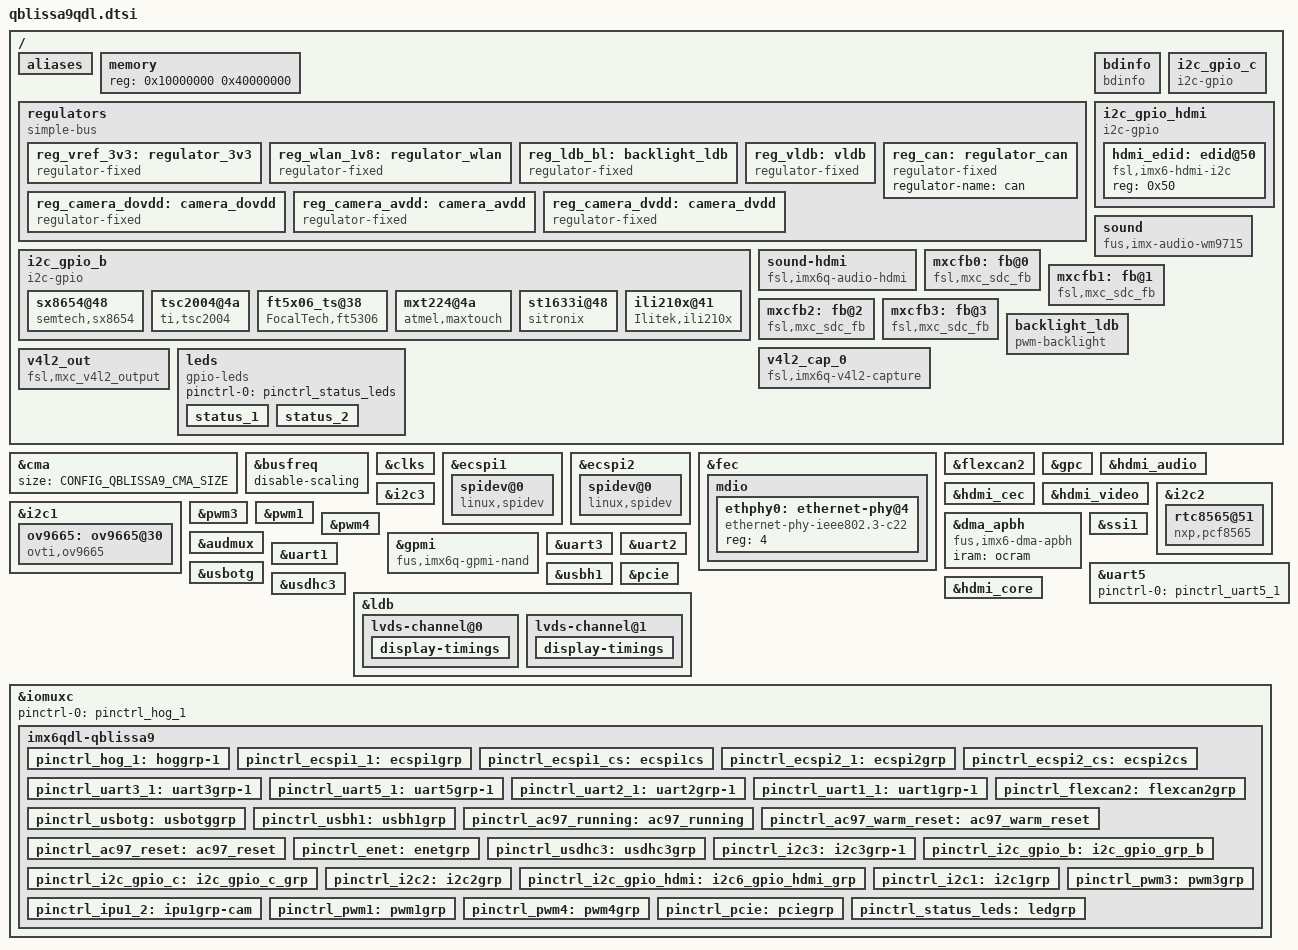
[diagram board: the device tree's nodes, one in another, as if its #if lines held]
/*
 * Copyright 2016-2017 F&S Elektronik Systeme GmbH
 *
 * This program is free software; you can redistribute it and/or modify
 * it under the terms of the GNU General Public License version 2 as
 * published by the Free Software Foundation.
 */

#include <dt-bindings/pwm/pwm.h>

/* Do we have HDMI? */
#if ((CONFIG_QBLISSA9_MXCFB0 == DISPLAY_HDMI) \
    || (CONFIG_QBLISSA9_MXCFB1 == DISPLAY_HDMI) \
    || (CONFIG_QBLISSA9_MXCFB2 == DISPLAY_HDMI) \
    || (CONFIG_QBLISSA9_MXCFB3 == DISPLAY_HDMI))
#define CONFIG_QBLISSA9_HDMI
#define CONFIG_QBLISSA9_HDMI_AUDIO
#define CONFIG_QBLISSA9_HDMI_CEC
#if ((CONFIG_QBLISSA9_MXCFB0 == DISPLAY_HDMI) \
    || (CONFIG_QBLISSA9_MXCFB1 == DISPLAY_HDMI))
#define __HDMI_ON_0_OR_1__	1
#define __HDMI_ON_2_OR_3__	0
#else
#define __HDMI_ON_0_OR_1__	0
#define __HDMI_ON_2_OR_3__	1
#endif
#endif

/* Do we have LVDS0? */
#if ((CONFIG_QBLISSA9_MXCFB0 == DISPLAY_LVDS0) \
    || (CONFIG_QBLISSA9_MXCFB1 == DISPLAY_LVDS0) \
    || (CONFIG_QBLISSA9_MXCFB2 == DISPLAY_LVDS0) \
    || (CONFIG_QBLISSA9_MXCFB3 == DISPLAY_LVDS0))
#define CONFIG_QBLISSA9_LVDS0
#if ((CONFIG_QBLISSA9_MXCFB0 == DISPLAY_LVDS0) \
    || (CONFIG_QBLISSA9_MXCFB1 == DISPLAY_LVDS0))
#define __LVDS0_ON_0_OR_1__	1
#define __LVDS0_ON_2_OR_3__	0
#else
#define __LVDS0_ON_0_OR_1__	0
#define __LVDS0_ON_2_OR_3__	1
#endif
#endif

/* Do we have LVDS1? */
#if ((CONFIG_QBLISSA9_MXCFB0 == DISPLAY_LVDS1) \
    || (CONFIG_QBLISSA9_MXCFB1 == DISPLAY_LVDS1) \
    || (CONFIG_QBLISSA9_MXCFB2 == DISPLAY_LVDS1) \
    || (CONFIG_QBLISSA9_MXCFB3 == DISPLAY_LVDS1))
#define CONFIG_QBLISSA9_LVDS1
#if ((CONFIG_QBLISSA9_MXCFB0 == DISPLAY_LVDS1) \
    || (CONFIG_QBLISSA9_MXCFB1 == DISPLAY_LVDS1))
#define __LVDS1_ON_0_OR_1__	1
#define __LVDS1_ON_2_OR_3__	0
#else
#define __LVDS1_ON_0_OR_1__	0
#define __LVDS1_ON_2_OR_3__	1
#endif
#endif

/* Check which LVDS will be the primary display */
#if (CONFIG_QBLISSA9_MXCFB0 == DISPLAY_LVDS0)
#define __LVDS0_PRIMARY__
#elif (CONFIG_QBLISSA9_MXCFB0 == DISPLAY_LVDS1)
#define __LVDS1_PRIMARY__
#elif (CONFIG_QBLISSA9_MXCFB1 == DISPLAY_LVDS0)
#define __LVDS0_PRIMARY__
#elif (CONFIG_QBLISSA9_MXCFB1 == DISPLAY_LVDS1)
#define __LVDS1_PRIMARY__
#elif (CONFIG_QBLISSA9__MXCFB2 == DISPLAY_LVDS0)
#define __LVDS0_PRIMARY__
#elif (CONFIG_QBLISSA9_MXCFB2 == DISPLAY_LVDS1)
#define __LVDS1_PRIMARY__
#elif (CONFIG_QBLISSA9_MXCFB3 == DISPLAY_LVDS0)
#define __LVDS0_PRIMARY__
#elif (CONFIG_QBLISSA9_MXCFB3 == DISPLAY_LVDS1)
#define __LVDS1_PRIMARY__
#endif

/* Check for invalid CONFIG combinations */

/* If SD_A is not active, also CD, WP and bus width may not be used */
#ifndef CONFIG_QBLISSA9_SD_A
#undef CONFIG_QBLISSA9_SD_A_CD
#undef CONFIG_QBLISSA9_SD_A_WP
#undef CONFIG_QBLISSA9_SD_A_8BIT
#endif

/ {
	aliases {
		mxcfb0 = &mxcfb0;
		mxcfb1 = &mxcfb1;
		mxcfb2 = &mxcfb2;
		mxcfb3 = &mxcfb3;
#ifdef CONFIG_QBLISSA9_I2C_B
		i2c3 = &i2c_gpio_b;
#endif
#ifdef CONFIG_QBLISSA9_I2C_C
		i2c4 = &i2c_gpio_c;
#endif
#ifdef CONFIG_QBLISSA9_HDMI
		i2c5 = &i2c_gpio_hdmi;
#endif
		};

	memory {
		reg = <0x10000000 0x40000000>;
	};

	regulators {
		compatible = "simple-bus";

		reg_vref_3v3: regulator_3v3 {
			compatible = "regulator-fixed";
			regulator-name = "vref-3V3";
			regulator-min-microvolt = <3300000>;
			regulator-max-microvolt = <3300000>;
			regulator-always-on;
		};

		/* USB_OTG_PWR handled by USB controller, no regulator needed */
#if 0 //###
		reg_usb_otg_vbus: usb_otg_vbus {
			compatible = "regulator-fixed";
			regulator-name = "usb_otg_vbus";
			regulator-min-microvolt = <5000000>;
			regulator-max-microvolt = <5000000>;
			/* Switchable starting with board rev. 1.30 */
#if CONFIG_QBLISSA9_BOARD_REVISION < 130
			regulator-always-on;
#else
			gpio = <&gpio3 22 GPIO_ACTIVE_HIGH>;
#endif
		};
#endif //###

		/* USB_H1_PWR is always on, no regulator needed */
#if 0 //###
		reg_usb_h1_vbus: usb_h1_vbus {
			compatible = "regulator-fixed";
			regulator-name = "usb_h1_vbus";
			regulator-min-microvolt = <5000000>;
			regulator-max-microvolt = <5000000>;
			/* No way to switch USB1_H1_VBUS power */
		};
#endif //###

#ifdef CONFIG_QBLISSA9_WLAN
		reg_wlan_1v8: regulator_wlan {
			compatible = "regulator-fixed";
			regulator-name = "vqmmc-wlan-1v8";
			regulator-min-microvolt = <1800000>;
			regulator-max-microvolt = <1800000>;
			regulator-always-on;
		};
#endif

		/* LVDS backlight */
		reg_ldb_bl: backlight_ldb {
			compatible = "regulator-fixed";
			regulator-name = "ldb-bl";
			gpio = <&gpio2 8 GPIO_ACTIVE_HIGH>;
			regulator-min-microvolt = <3300000>;
			regulator-max-microvolt = <3300000>;
			enable-active-high;
		};

		/* LVDS logic supply power */
		reg_vldb: vldb {
			compatible = "regulator-fixed";
			regulator-name = "VLDB";
			gpio = <&gpio2 11 GPIO_ACTIVE_HIGH>;
			regulator-min-microvolt = <3300000>;
			regulator-max-microvolt = <3300000>;
			enable-active-high;
		};

		/* CAN */
		reg_can: regulator_can {
			compatible = "regulator-fixed";
			regulator-name = "can";
		};

#ifdef CONFIG_QBLISSA9_PARALLEL_CAMERA
		reg_camera_dovdd: camera_dovdd {
			compatible = "regulator-fixed";
			regulator-name = "DOVDD-supply";
			regulator-min-microvolt = <1800000>;
			regulator-max-microvolt = <1800000>;
		};

		reg_camera_avdd: camera_avdd {
			compatible = "regulator-fixed";
			regulator-name = "VAVDD-supply";
			regulator-min-microvolt = <2800000>;
			regulator-max-microvolt = <2800000>;
		};

		reg_camera_dvdd: camera_dvdd {
			compatible = "regulator-fixed";
			regulator-name = "DVDD-supply";
			regulator-min-microvolt = <1500000>;
			regulator-max-microvolt = <1500000>;
		};
#endif /* CONFIG_QBLISSA9_PARALLEL_CAMERA */
	};

	/* F&S board information */
	bdinfo: bdinfo {
		compatible = "bdinfo";
		board_name = "qblissa9";
		ecc_strength = "8";
	};

#ifdef CONFIG_QBLISSA9_I2C_B
	i2c_gpio_b: i2c_gpio_b {
		compatible = "i2c-gpio";
		gpios = <&gpio4 21 GPIO_ACTIVE_HIGH /* sda */
			 &gpio4 22 GPIO_ACTIVE_HIGH /* scl */
			>;
		pinctrl-names = "default";
		pinctrl-0 = <&pinctrl_i2c_gpio_b>;
		i2c-gpio,delay-us = <2>;	/* ~100 kHz */
		#address-cells = <1>;
		#size-cells = <0>;
	};
#endif

#ifdef CONFIG_QBLISSA9_I2C_C
	i2c_gpio_c: i2c_gpio_c {
		compatible = "i2c-gpio";
		gpios = <&gpio2 12 GPIO_ACTIVE_HIGH /* sda */
			 &gpio2 13 GPIO_ACTIVE_HIGH /* scl */
			>;
		pinctrl-names = "default";
		pinctrl-0 = <&pinctrl_i2c_gpio_c>;
		i2c-gpio,delay-us = <2>;	/* ~100 kHz */
		#address-cells = <1>;
		#size-cells = <0>;
	};
#endif

#ifdef CONFIG_QBLISSA9_HDMI
	i2c_gpio_hdmi: i2c_gpio_hdmi {
		compatible = "i2c-gpio";
		gpios = <&gpio2 14 GPIO_ACTIVE_HIGH /* sda */
			 &gpio2 15 GPIO_ACTIVE_HIGH /* scl */
			>;
		pinctrl-names = "default";
		pinctrl-0 = <&pinctrl_i2c_gpio_hdmi>;
		//i2c-gpio,sda-open-drain;
		//i2c-gpio,scl-open-drain;
		i2c-gpio,delay-us = <2>;	/* ~100 kHz */
		#address-cells = <1>;
		#size-cells = <0>;
	};
#endif

#ifdef CONFIG_QBLISSA9_WM9715_AUDIO
	sound {
		compatible = "fus,imx-audio-wm9715";
		fus,model = "F&S Audio WM9715";
		audio-cpu = <&ssi1>;
		clocks = <&clks IMX6QDL_CLK_DUMMY>;
		mux-int-port = <1>;  /* SSI1=1, SSI2=2, SSI3=7 */
		mux-ext-port = <6>;
	};
#endif

#ifdef CONFIG_QBLISSA9_HDMI_AUDIO
	sound-hdmi {
		compatible = "fsl,imx6q-audio-hdmi", "fsl,imx-audio-hdmi";
		model = "imx-audio-hdmi";
		hdmi-controller = <&hdmi_audio>;
	};
#endif

	mxcfb0: fb@0 {
		compatible = "fsl,mxc_sdc_fb";
		late_init = <0>;
#if (CONFIG_QBLISSA9_MXCFB0 == DISPLAY_HDMI)
		disp_dev = "hdmi";
		default_bpp = <CONFIG_QBLISSA9_HDMI_BPP>;
		interface_pix_fmt = CONFIG_QBLISSA9_HDMI_PIX_FMT;
		int_clk = <0>;
		mode_str = CONFIG_QBLISSA9_HDMI_MODE_STR;
#elif (CONFIG_QBLISSA9_MXCFB0 == DISPLAY_LVDS0)
		disp_dev = "ldb";
		default_bpp = <CONFIG_QBLISSA9_LVDS0_BPP>;
		interface_pix_fmt = CONFIG_QBLISSA9_LVDS0_PIX_FMT;
		int_clk = <1>;
#elif (CONFIG_QBLISSA9_MXCFB0 == DISPLAY_LVDS1)
		disp_dev = "ldb";
		default_bpp = <CONFIG_QBLISSA9_LVDS1_BPP>;
		interface_pix_fmt = CONFIG_QBLISSA9_LVDS1_PIX_FMT;
		int_clk = <1>;
#else
		status = "disabled";
#endif
	};

	mxcfb1: fb@1 {
		compatible = "fsl,mxc_sdc_fb";
		late_init = <0>;
#if (CONFIG_QBLISSA9_MXCFB1 == DISPLAY_HDMI)
		disp_dev = "hdmi";
		default_bpp = <CONFIG_QBLISSA9_HDMI_BPP>;
		interface_pix_fmt = CONFIG_QBLISSA9_HDMI_PIX_FMT;
		int_clk = <0>;
		mode_str = CONFIG_QBLISSA9_HDMI_MODE_STR;
#elif (CONFIG_QBLISSA9_MXCFB1 == DISPLAY_LVDS0)
		disp_dev = "ldb";
		default_bpp = <CONFIG_QBLISSA9_LVDS0_BPP>;
		interface_pix_fmt = CONFIG_QBLISSA9_LVDS0_PIX_FMT;
		int_clk = <1>;
#elif (CONFIG_QBLISSA9_MXCFB1 == DISPLAY_LVDS1)
		disp_dev = "ldb";
		default_bpp = <CONFIG_QBLISSA9_LVDS1_BPP>;
		interface_pix_fmt = CONFIG_QBLISSA9_LVDS1_PIX_FMT;
		int_clk = <1>;
#else
		status = "disabled";
#endif
	};

	mxcfb2: fb@2 {
		compatible = "fsl,mxc_sdc_fb";
		late_init = <0>;
#if (CONFIG_QBLISSA9_MXCFB2 == DISPLAY_HDMI)
		disp_dev = "hdmi";
		default_bpp = <CONFIG_QBLISSA9_HDMI_BPP>;
		interface_pix_fmt = CONFIG_QBLISSA9_HDMI_PIX_FMT;
		int_clk = <0>;
		mode_str = CONFIG_QBLISSA9_HDMI_MODE_STR;
#elif (CONFIG_QBLISSA9_MXCFB2 == DISPLAY_LVDS0)
		disp_dev = "ldb";
		default_bpp = <CONFIG_QBLISSA9_LVDS0_BPP>;
		interface_pix_fmt = CONFIG_QBLISSA9_LVDS0_PIX_FMT;
		int_clk = <1>;
#elif (CONFIG_QBLISSA9_MXCFB2 == DISPLAY_LVDS1)
		disp_dev = "ldb";
		default_bpp = <CONFIG_QBLISSA9_LVDS1_BPP>;
		interface_pix_fmt = CONFIG_QBLISSA9_LVDS1_PIX_FMT;
		int_clk = <1>;
#else
		status = "disabled";
#endif
	};

	mxcfb3: fb@3 {
		compatible = "fsl,mxc_sdc_fb";
		late_init = <0>;
#if (CONFIG_QBLISSA9_MXCFB3 == DISPLAY_HDMI)
		disp_dev = "hdmi";
		default_bpp = <CONFIG_QBLISSA9_HDMI_BPP>;
		interface_pix_fmt = CONFIG_QBLISSA9_HDMI_PIX_FMT;
		int_clk = <0>;
		mode_str = CONFIG_QBLISSA9_HDMI_MODE_STR;
#elif (CONFIG_QBLISSA9_MXCFB3 == DISPLAY_LVDS0)
		disp_dev = "ldb";
		default_bpp = <CONFIG_QBLISSA9_LVDS0_BPP>;
		interface_pix_fmt = CONFIG_QBLISSA9_LVDS0_PIX_FMT;
		int_clk = <1>;
#elif (CONFIG_QBLISSA9_MXCFB3 == DISPLAY_LVDS1)
		disp_dev = "ldb";
		default_bpp = <CONFIG_QBLISSA9_LVDS1_BPP>;
		interface_pix_fmt = CONFIG_QBLISSA9_LVDS1_PIX_FMT;
		int_clk = <1>;
#else
		status = "disabled";
#endif
	};

	/* LVDS backlight PWM (PWM3) */
	backlight_ldb {
		compatible = "pwm-backlight";
		power-supply = <&reg_ldb_bl>;
#ifndef DISPLAY_LVDS_CHIMEI
		pwms = <&pwm3 0 250000 PWM_POLARITY_INVERTED>;
		brightness-levels = <135 143 151 159 167 175 183 191
				     199 207 215 223 231 239 247 255>;
#else
		pwms = <&pwm3 0 5000000 0>;
		brightness-levels = <0 1 5 10 18 28 41 56
				     73 92 113 137 163 192 222 255>;
#endif
		default-brightness-level = <14>;
		fb-names = "ldb0", "ldb1";
	};

#ifdef CONFIG_QBLISSA9_PARALLEL_CAMERA
	/* Parallel camera interface */
	v4l2_cap_0 {
		compatible = "fsl,imx6q-v4l2-capture";
		ipu_id = <0>;
		csi_id = <0>;
		mclk_source = <0>;
		status = "okay";
	};
#endif

	v4l2_out {
		compatible = "fsl,mxc_v4l2_output";
		status = "okay";
	};

	leds {
		compatible = "gpio-leds";
		pinctrl-names = "default";
		pinctrl-0 = <&pinctrl_status_leds>;

		status_1 {
			label = "Status1";
			gpios = <&gpio4 6 GPIO_ACTIVE_HIGH>;
			default-state = "keep";
		};

		status_2 {
			label = "Status2";
			gpios = <&gpio4 7 GPIO_ACTIVE_HIGH>;
			default-state = "keep";
		};
	};
};

/* RAM size for Continuous Memory Allocator; if not defined, use 320 MB */
#ifndef CONFIG_QBLISSA9_CMA_SIZE
#define CONFIG_QBLISSA9_CMA_SIZE 0x14000000
#endif
&cma {
	size = <CONFIG_QBLISSA9_CMA_SIZE>;
};

&busfreq {
	/* Disable bus frequency scaling, because reducing bus frequency to
	   24 MHz does not work with all types of DDR3 RAM */
	disable-scaling;
};

/* if you want to use the pmic controller you have to set the arm-supply and
 * the soc-supply to the regulator of the pmic. Look pfuze comment.*/
#if 0
&cpu0 {
	arm-supply = <&sw1a_reg>;
	soc-supply = <&sw1c_reg>;
};
#endif

&clks {
	assigned-clocks =
#ifdef CONFIG_QBLISSA9_LVDS0_CLK
			  <&clks IMX6QDL_CLK_LDB_DI0_SEL>,
#endif
#ifdef CONFIG_QBLISSA9_LVDS1_CLK
			  <&clks IMX6QDL_CLK_LDB_DI1_SEL>,
#endif
			  <&clks IMX6QDL_CLK_PLL4_AUDIO_DIV>,
			  <&clks IMX6QDL_CLK_SSI1_SEL>,
			  <&clks IMX6QDL_CLK_SSI1>;

	assigned-clock-parents =
#ifdef CONFIG_QBLISSA9_LVDS0_CLK
				 <&clks CONFIG_QBLISSA9_LVDS0_CLK>,
#endif
#ifdef CONFIG_QBLISSA9_LVDS1_CLK
				 <&clks CONFIG_QBLISSA9_LVDS1_CLK>,
#endif
			         <0>,
				 <&clks IMX6QDL_CLK_PLL4_AUDIO_DIV>;

	/*
	 * The Audio-PLL (PLL4) must have at least 650MHz. The PLL post divider
	 * can divide by 1, 2 and 4, which means the lowest possible frequency
	 * is 162.5 MHz. Use 196.608 MHz, which is a multiple of 24.576 MHz.
	 * This is in turn a multiple of the commonly used audio bit rates.
	 */
	assigned-clock-rates =
#ifdef CONFIG_QBLISSA9_LVDS0_CLK
				<0>,
#endif
#ifdef CONFIG_QBLISSA9_LVDS1_CLK
				<0>,
#endif
				<196608000>,
				<196608000>,
				<24576000>;
};

#ifdef CONFIG_QBLISSA9_SPI_FLASH
&ecspi1 {
	fsl,spi-num-chipselects = <1>;
	cs-gpios = <&gpio2 30 GPIO_ACTIVE_HIGH>;
	pinctrl-names = "default";
	pinctrl-0 = <&pinctrl_ecspi1_1 &pinctrl_ecspi1_cs>;
	status = "okay";

	spidev@0 {
		#address-cells = <1>;
		#size-cells = <1>;
		compatible = "linux,spidev";
		spi-max-frequency = <20000000>;
		reg = <0>;
	};
};
#endif /* CONFIG_QBLISSA9_SPI_FLASH */

#ifdef CONFIG_QBLISSA9_SPI_A
/* SPI_A (2x CS) */
&ecspi2 {
	fsl,spi-num-chipselects = <2>;
	cs-gpios = <&gpio2 26 0>,
		<&gpio2 27 0>;
	pinctrl-names = "default";
	pinctrl-0 = <&pinctrl_ecspi2_1 &pinctrl_ecspi2_cs>;
	status = "okay";

	spidev@0 {
		#address-cells = <1>;
		#size-cells = <1>;
		compatible = "linux,spidev";
		spi-max-frequency = <20000000>;
		reg = <0>;
	};
};
#endif /* CONFIG_QBLISSA9_SPI_A */

&fec {
	pinctrl-names = "default";
	pinctrl-0 = <&pinctrl_enet>;
	phy-mode = "rgmii-id";
	phy-handle = <&ethphy0>;
	phy-supply = <&reg_vref_3v3>;
	status = "okay";

	mdio {
		#address-cells = <1>;
		#size-cells = <0>;

		ethphy0: ethernet-phy@4 {
			compatible = "ethernet-phy-ieee802.3-c22";
			reg = <4>;
			/* Set the maximum link speed if required */
			//max-speed = <100>;
		};
	};
};

/* CAN_A implemented by FLEXCAN2 */
&flexcan2 {
	pinctrl-names = "default";
	pinctrl-0 = <&pinctrl_flexcan2>;
	xceiver-supply = <&reg_can>;
	status = "okay";
};

&gpc {
	fsl,cpu_pupscr_sw2iso = <0xf>;
	fsl,cpu_pupscr_sw = <0xf>;
	fsl,cpu_pdnscr_iso2sw = <0x1>;
	fsl,cpu_pdnscr_iso = <0x1>;
	/* more information how to ldo-bypass look at pfuze comment in i2c2 */
	fsl,ldo-bypass = <0>; /* use ldo-bypass, u-boot will check it and configure */
	fsl,wdog-reset = <1>; /* watchdog select of reset source */
};

#ifdef CONFIG_QBLISSA9_HDMI_AUDIO
&hdmi_audio {
	status = "okay";
};
#endif

#ifdef CONFIG_QBLISSA9_HDMI_CEC
&hdmi_cec {
//###	pinctrl-names = "default";
//###	pinctrl-0 = <&pinctrl_hdmi_cec_1>;
	status = "okay";
};
#endif

#ifdef CONFIG_QBLISSA9_HDMI
&hdmi_video {
	fsl,phy_reg_vlev = <0x0294>;
	fsl,phy_reg_cksymtx = <0x800d>;
	hpd-active-low;
	force-dvi-mode;
	status = "okay";
};
#endif

#ifdef CONFIG_QBLISSA9_I2C_D
/* I2C2 is used for internal communication (RTC, PMIC), always active */
&i2c2 {
	clock-frequency = <100000>;
	pinctrl-names = "default";
	pinctrl-0 = <&pinctrl_i2c2>;
	status = "okay";

	rtc8565@51 {
		compatible = "nxp,pcf8565", "nxp,pcf8563";
		reg = <0x51>;
		interrupt-parent = <&gpio1>;
		interrupts = <28 IRQ_TYPE_EDGE_FALLING>;
	};
/*
 * If you want to use PMIC you have to set these regulators. But the PMIC
 * control register will be set by UBoot so if you want use it you have to
 * implement that the pmu_reg_core register will be set to "Power FET switched
 * fully on", because this sets the bypass and PMIC can control the voltage.
 */
#if 0
	pmic: pfuze100@08 {
		compatible = "fsl,pfuze100";
		reg = <0x08>;

		regulators {
			sw1a_reg: sw1ab {
				regulator-min-microvolt = <300000>;
				regulator-max-microvolt = <1875000>;
				regulator-boot-on;
				regulator-always-on;
				regulator-ramp-delay = <6250>;
			};

			sw1c_reg: sw1c {
				regulator-min-microvolt = <300000>;
				regulator-max-microvolt = <1875000>;
				regulator-boot-on;
				regulator-always-on;
				regulator-ramp-delay = <6250>;
			};

			sw2_reg: sw2 {
				//regulator-min-microvolt = <800000>;
				regulator-min-microvolt = <400000>;
				regulator-max-microvolt = <3300000>;
				regulator-boot-on;
				regulator-always-on;
				regulator-ramp-delay = <6250>;
			};

			sw3a_reg: sw3a {
				regulator-min-microvolt = <400000>;
				//regulator-max-microvolt = <1975000>;
				regulator-max-microvolt = <3300000>;
				regulator-boot-on;
				regulator-always-on;
			};

			sw3b_reg: sw3b {
				regulator-min-microvolt = <400000>;
				//regulator-max-microvolt = <1975000>;
				regulator-max-microvolt = <3300000>;
				regulator-boot-on;
				regulator-always-on;
			};

			sw4_reg: sw4 {
				//regulator-min-microvolt = <800000>;
				regulator-min-microvolt = <400000>;
				regulator-max-microvolt = <3300000>;
			};

			swbst_reg: swbst {
				regulator-min-microvolt = <5000000>;
				regulator-max-microvolt = <5150000>;
			};

			snvs_reg: vsnvs {
				regulator-min-microvolt = <1000000>;
				regulator-max-microvolt = <3000000>;
				regulator-boot-on;
				regulator-always-on;
			};

			vref_reg: vrefddr {
				regulator-boot-on;
				regulator-always-on;
			};

			vgen1_reg: vgen1 {
				regulator-min-microvolt = <800000>;
				regulator-max-microvolt = <1550000>;
			};

			vgen2_reg: vgen2 {
				regulator-min-microvolt = <800000>;
				regulator-max-microvolt = <1550000>;
			};

			vgen3_reg: vgen3 {
				regulator-min-microvolt = <1800000>;
				regulator-max-microvolt = <3300000>;
			};

			vgen4_reg: vgen4 {
				regulator-min-microvolt = <1800000>;
				regulator-max-microvolt = <3300000>;
				regulator-always-on;
			};

			vgen5_reg: vgen5 {
				regulator-min-microvolt = <1800000>;
				regulator-max-microvolt = <3300000>;
				regulator-always-on;
			};

			vgen6_reg: vgen6 {
				regulator-min-microvolt = <1800000>;
				regulator-max-microvolt = <3300000>;
				regulator-always-on;
			};
		};
	};
#endif
};
#endif

#ifdef CONFIG_QBLISSA9_I2C_A
/* I2C_A implemented via I2C3 */
&i2c3 {
	clock-frequency = <100000>;
	pinctrl-names = "default";
	pinctrl-0 = <&pinctrl_i2c3>;
	status = "okay";

	/* Add devices here */
};
#endif /* CONFIG_QBLISSA9_I2C_A */

#ifdef CONFIG_QBLISSA9_I2C_B
/* I2C_B implemented as Soft-I2C (SMB, with IRQ, used for touches) */
&i2c_gpio_b {
#ifdef CONFIG_QBLISSA9_4WTOUCH_SX8655
	/* 4/5 wire analog resistive touch */
	sx8654@48 {
		compatible = "semtech,sx8654";
		reg = <0x48>;
		touchrate = <0x30>;
		powdly = <0x06>;
		filt = <0x02>;
		setdly = <0x08>;
		pinctrl-names = "default";
		interrupt-parent = <&gpio4>;
		interrupts = <23 IRQ_TYPE_EDGE_FALLING>;
		reset-gpio = <&gpio4 31 GPIO_ACTIVE_LOW>;
	};
#endif

#ifdef CONFIG_QBLISSA9_4WTOUCH_TSC2004
	/* 4/5 wire analog resistive touch */
	tsc2004@4a {
		compatible = "ti,tsc2004";
		reg = <0x4a>;
		vio-supply = <&reg_vref_3v3>;
		interrupts-extended = <&gpio4 23 IRQ_TYPE_EDGE_FALLING>;
		reset-gpio = <&gpio4 31 GPIO_ACTIVE_LOW>;
		touchscreen-fuzz-x = <4>;
		touchscreen-fuzz-y = <7>;
		touchscreen-fuzz-pressure = <20>;
		touchscreen-size-x = <4096>;
		touchscreen-size-y = <4096>;
		touchscreen-max-pressure = <2048>;
		touchscreen-inverted-y;
		ti,x-plate-ohms = <280>;
		ti,pre-charge-time = <4>;
		ti,sense-time-sel = <3>;
	};
#endif

#ifdef CONFIG_QBLISSA9_CAPTOUCH_FT5x06
	/* F&S driver V3.0 */
	ft5x06_ts@38 {
		compatible = "FocalTech,ft5306";
		reg = <0x38>;
		fingers = <2>;
		touchscreen-size-x = <800>;
		touchscreen-size-y = <480>;
		threshold = <25>;
		interrupt-parent = <&gpio4>;
		interrupts = <23 IRQ_TYPE_EDGE_FALLING>;
		reset-gpios = <&gpio4 31 GPIO_ACTIVE_LOW>;
		x-rev;
		y-rev;
		linux,wakeup;
	};
#endif

#ifdef CONFIG_QBLISSA9_CAPTOUCH_MXT224
	/* Atmel PCAP touch */
	mxt224@4a {
		compatible = "atmel,maxtouch";
		reg = <0x4a>;
		interrupt-parent = <&gpio4>;
		interrupts = <23 IRQ_TYPE_EDGE_FALLING>;
		atmel,cfg_name = "atmel/mxt224.cfg";
		atmel,reset-gpio = <&gpio4 31 GPIO_ACTIVE_LOW>;
	};
#endif

#ifdef CONFIG_QBLISSA9_CAPTOUCH_SITRONIX
	/* Sitronix PCAP touch */
	st1633i@48 {
		compatible = "sitronix";
		reg = <0x48>;
		swap-xy;
		interrupt-parent = <&gpio4>;
		interrupts = <23 IRQ_TYPE_EDGE_FALLING>;
		reset-gpio = <&gpio4 31 GPIO_ACTIVE_LOW>;
	};
#endif

#ifdef CONFIG_QBLISSA9_CAPTOUCH_ILITEK
	/* Ilitek PCAP touch */
	ili210x@41 {
		compatible = "Ilitek,ili210x";
		reg = <0x41>;
		interrupt-parent = <&gpio4>;
		interrupts = <23 IRQ_TYPE_EDGE_FALLING>;
		reset-gpio = <&gpio4 31 GPIO_ACTIVE_LOW>;
	};
#endif
};
#endif

#ifdef CONFIG_QBLISSA9_I2C_C
/* I2C_C implemented as Soft-I2C */
&i2c_gpio_c {
	/* Add devices here */
};
#endif

#ifdef CONFIG_QBLISSA9_HDMI
&i2c_gpio_hdmi {
	hdmi_edid: edid@50 {
		compatible = "fsl,imx6-hdmi-i2c";
		reg = <0x50>;
	};
};
#endif

#ifdef CONFIG_QBLISSA9_PARALLEL_CAMERA /* NOT TESTED */
&i2c1 {
	clock-frequency = <100000>;
	pinctrl-names = "default";
	pinctrl-0 = <&pinctrl_i2c1>;
	status = "okay";

	ov9665: ov9665@30 {
		compatible = "ovti,ov9665";
		reg = <0x30>;
		pinctrl-names = "default";
		pinctrl-0 = <&pinctrl_ipu1_2>;
		clocks = <&clks IMX6QDL_CLK_CKO>;
		clock-names = "csi_mclk";
		DOVDD-supply = <&reg_camera_dovdd>; /* 1.8v */
		AVDD-supply = <&reg_camera_avdd>;  /* 2.8v, rev C board is VGEN3
						rev B board is VGEN5 */
		DVDD-supply = <&reg_camera_dvdd>;  /* 1.5v*/
		pwn-gpios = <&gpio5 24 GPIO_ACTIVE_HIGH>;
		rst-gpios = <&gpio5 23 GPIO_ACTIVE_LOW>;
		csi_id = <0>;
		mclk = <24000000>;
		mclk_source = <0>;
	};
};
#endif

#ifdef CONFIG_QBLISSA9_PWM_A
/* PWM_A/LVDS_BLT_CTRL, pin 123 */
&pwm3 {
	pinctrl-names = "default";
	pinctrl-0 = <&pinctrl_pwm3>;
	#pwm-cells = <3>;
	keep-power;		/* Necessary if PWM is inverted */
	status = "okay";
};
#endif


#ifdef CONFIG_QBLISSA9_PWM_B
/* PWM_B/FAN_PWMOUT, pin 196 */
&pwm1 {
	pinctrl-names = "default";
	pinctrl-0 = <&pinctrl_pwm1>;
	keep-power;		/* Necessary if PWM is inverted */
	status = "okay";
};
#endif

#ifdef CONFIG_QBLISSA9_PWM_C
/* PWM_C/SPKR, pin 194 */
&pwm4 {
	pinctrl-names = "default";
	pinctrl-0 = <&pinctrl_pwm4>;
	keep-power;		/* Necessary if PWM is inverted */
	status = "okay";
};
#endif

&dma_apbh {
	/* Switch to F&S implementation of APBH DMA driver for GPMI (NAND) */
	compatible = "fus,imx6-dma-apbh", "fus,imx28-dma-apbh";
	iram = <&ocram>;
};

#ifdef CONFIG_QBLISSA9_NAND
&gpmi {
	/* Switch to F&S implementation of GPMI NAND driver */
	compatible = "fus,imx6q-gpmi-nand";
	pinctrl-names = "default";
//###	pinctrl-0 = <&pinctrl_gpmi_nand_1>;
	fus,skipblocks = <2>;
	fus,chunk1k;
	fus,ecc_strength = <8>;		/* Spare area 64 bytes */
	//fus,ecc_strength = <40>;	/* Spare area 224 bytes */
	status = "okay";
};
#endif

#ifdef CONFIG_QBLISSA9_WM9715_AUDIO
&audmux {
	status = "okay";
};

&ssi1 {
	fsl,mode = "ac97-slave";
	cell-index = <0>;
	pinctrl-names = "ac97-running", "ac97-reset", "ac97-warm-reset";
	pinctrl-0 = <&pinctrl_ac97_running>;
	pinctrl-1 = <&pinctrl_ac97_reset>;
	pinctrl-2 = <&pinctrl_ac97_warm_reset>;
	ac97-gpios = <&gpio4 19 0 &gpio4 18 0 &gpio4 16 0>;
	status = "okay";
};
#endif

#ifdef CONFIG_QBLISSA9_UART_A
/* UART_A is implemented via UART3 */
&uart3 {
	pinctrl-names = "default";
	pinctrl-0 = <&pinctrl_uart3_1>;
	uart-has-rtscts;
	status = "okay";
};
#endif /* CONFIG_QBLISSA9_UART_A */

#ifdef CONFIG_QBLISSA9_UART_B
/* UART_B is implemented via UART5 */
&uart5 {
	pinctrl-names = "default";
	pinctrl-0 = <&pinctrl_uart5_1>;
	status = "okay";
};
#endif /* CONFIG_QBLISSA9_UART_B */

#ifdef CONFIG_QBLISSA9_UART_C
/* UART_C is implemented via UART2 */
&uart2 {
	pinctrl-names = "default";
	pinctrl-0 = <&pinctrl_uart2_1>;
	uart-has-rtscts;
	status = "okay";
};
#endif /* CONFIG_QBLISSA9_UART_C */

#ifdef CONFIG_QBLISSA9_BLUETOOTH
/* Bluetooth is accessed via HCI, implemented by UART1 */
&uart1 {
	pinctrl-names = "default";
	pinctrl-0 = <&pinctrl_uart1_1>;
	uart-has-rtscts;
	status = "okay";
};
#endif

&usbotg {
	pinctrl-names = "default";
	pinctrl-0 = <&pinctrl_usbotg>;
//###	vbus-supply = <&reg_usb_otg_vbus>;
	/* OTG ID pin has an issue; so set host or device role manually */
#ifdef CONFIG_QBLISSA9_USB_OTG_HOST
	dr_mode = "host";
#else
	dr_mode = "peripheral";
#endif
#ifdef CONFIG_QBLISSA9_HAVE_USB_OTG_OC
	over-current-active-low;
#else
	disable-over-current;
#endif
	status = "okay";
};

&usbh1 {
	pinctrl-names = "default";
	pinctrl-0 = <&pinctrl_usbh1>;
//###	vbus-supply = <&reg_usb_h1_vbus>;
	disable-over-current;
	status = "okay";
};

#if 0 /* NOT TESTED */
#ifdef CONFIG_QBLISSA9_WLAN
&usdhc1 {
	/* on-board WLAN/BT */
	pinctrl-names = "default";
	pinctrl-0 = <&pinctrl_usdhc1>;
	non-removable;
	bus-width = <4>;
	vmmc-supply = <&reg_vref_3v3>;	/* VDD */
	vqmmc-supply = <&reg_wlan_1v8>;	/* VDD_IO */
	voltage-ranges = <1800 1800>;
	keep-power-in-suspend;
	enable-sdio-wakeup;
	en-gpios=<&gpio1 10 GPIO_ACTIVE_HIGH>, <&gpio1 11 GPIO_ACTIVE_HIGH>;
	irq-gpios=<&gpio1 15 GPIO_ACTIVE_HIGH>;
	cd-gpios = <&gpio1 1 GPIO_ACTIVE_LOW>;
	status = "okay";
};
#endif
#endif

#ifdef CONFIG_QBLISSA9_SD_A
&usdhc3 {
	/* Micro-SD-Card-Slot, CD is active low */
	pinctrl-names = "default";
	pinctrl-0 = <&pinctrl_usdhc3>;
#ifdef CONFIG_QBLISSA9_SD_A_CD
	cd-gpios = <&gpio6 15 GPIO_ACTIVE_LOW>;
#else
	non-removable;
#endif
#ifdef CONFIG_QBLISSA9_SD_A_WP
	wp-gpios = <&gpio1 13 GPIO_ACTIVE_HIGH>;
#endif
#ifdef CONFIG_QBLISSA9_SD_A_8BIT
	bus-width = <8>;		/* For example eMMC */
#else
	bus-width = <4>;
#endif
	vmmc-supply = <&reg_vref_3v3>;	/* VDD */
	vqmmc-supply = <&reg_vref_3v3>;	/* VDD_IO */
	no-1-8-v;
	keep-power-in-suspend;
	status = "okay";
};
#endif /* CONFIG_QBLISSA9_SD_A */

#ifdef CONFIG_QBLISSA9_PCIE
&pcie {
	pinctrl-names = "default";
	pinctrl-0 = <&pinctrl_pcie>;
#if (CONFIG_QBLISSA9_BOARD_REVISION >= 120)
	power-on-gpio = <&gpio1 8 GPIO_ACTIVE_LOW>;
#endif
	reset-gpio = <&gpio4 31 GPIO_ACTIVE_LOW>;
	status = "okay";
};
#endif

#ifdef CONFIG_QBLISSA9_HDMI
&hdmi_core {
#ifdef CONFIG_QBLISSA9_USE_ONE_IPU
	/*
	 * When using one IPU (id=0):
	 * HDMI can go to DI1, unless LVDS1 is also active. In this case LVDS1
	 * must go to DI1 and HDMI to DI0.
	 */
	ipu_id = <0>;
#if (__HDMI_ON_0_OR_1__ && __LVDS1_ON_0_OR_1__)
	disp_id = <0>;
#else
	disp_id = <1>;
#endif
#else /* !CONFIG_QBLISSA9_USE_ONE_IPU */
	/*
	 * When using two IPUs:
 	 * HDMI can always go to IPU2 (id=1), DI1.
	 */
	disp_id = <1>;
	ipu_id = <0>;
#endif /* CONFIG_QBLISSA9_USE_ONE_IPU */
	status = "okay";
};
#endif

#if (defined(CONFIG_QBLISSA9_LVDS0) || defined(CONFIG_QBLISSA9_LVDS1))
&ldb {
	ext_ref;
#if defined(CONFIG_QBLISSA9_LVDS_SPLIT_MODE)
	split-mode;
#elif defined(CONFIG_QBLISSA9_LVDS_DUAL_MODE)
	dual-mode;
#endif
	ldb-supply = <&reg_vldb>;
	status = "okay";

#ifdef CONFIG_QBLISSA9_LVDS0
	/* LVDS0 must always go to DI0 of an IPU! */
	lvds-channel@0 {
		reg = <0>;
#ifdef CONFIG_QBLISSA9_USE_ONE_IPU
		crtc = "ipu1-di0";
#else
		crtc = "ipu2-di0";
#endif
		fsl,data-mapping = CONFIG_QBLISSA9_LVDS0_MAPPING;
		fsl,data-width = <CONFIG_QBLISSA9_LVDS0_DATA_WIDTH>;
#ifdef __LVDS0_PRIMARY__
		primary;
#endif
		status = "okay";

		display-timings {
			native-mode = <&timing0>;
			timing0: CONFIG_QBLISSA9_LVDS0_TIMING;
		};
	};
#endif

#ifdef CONFIG_QBLISSA9_LVDS1
	/* LVDS1 must always go to DI1 of an IPU! */
	lvds-channel@1 {
#if defined(CONFIG_QBLISSA9_LVDS_DUAL_MODE) \
	|| defined(CONFIG_QBLISSA9_LVDS_SPLIT_MODE)
		reg = <0>;
#else
		reg = <1>;
#endif
#if (defined(CONFIG_QBLISSA9_USE_ONE_IPU) \
	|| (__LVDS0_ON_0_OR_1__ && __LVDS1_ON_0_OR_1__) \
	|| (__LVDS0_ON_2_OR_3__ && __LVDS1_ON_2_OR_3__))
		crtc = "ipu1-di1";
#else
		crtc = "ipu2-di1";
#endif
		fsl,data-mapping = CONFIG_QBLISSA9_LVDS1_MAPPING;
		fsl,data-width = <CONFIG_QBLISSA9_LVDS1_DATA_WIDTH>;
#ifdef __LVDS1_PRIMARY__
		primary;
#endif
		status = "okay";

		display-timings {
			native-mode = <&timing1>;
			timing1: CONFIG_QBLISSA9_LVDS1_TIMING;
		};
	};
#endif
};
#endif /* CONFIG_QBLISSA9_LVDS0 || CONFIG_QBLISSA9_LVDS1 */

&iomuxc {
	pinctrl-names = "default";
	pinctrl-0 = <&pinctrl_hog_1>;

	imx6qdl-qblissa9  {
		/* Pin configs that don't belong anywhere else */
		pinctrl_hog_1: hoggrp-1 {
			fsl,pins = <
				/* LVDS_PPEN */
				MX6QDL_PAD_SD4_DAT3__GPIO2_IO11		0x030b0

				/* BACKLIGHT_ON */
				MX6QDL_PAD_SD4_DAT0__GPIO2_IO08		0x030b0

				/* WDOG1 */
				MX6QDL_PAD_GPIO_9__WDOG1_B		0x0b0b0
				/* RTC_IRQ */
				MX6QDL_PAD_ENET_TX_EN__GPIO1_IO28	0x0b0b0
				/* SUSPEND S5*/
				MX6QDL_PAD_KEY_COL2__GPIO4_IO10		0x0b0b0
				/* SUSPEND STAT */
				MX6QDL_PAD_KEY_ROW2__GPIO4_IO11		0x0b0b0
				/* FAN_TACHOMETER INPUT */
				MX6QDL_PAD_GPIO_2__GPIO1_IO02		0x030b0
				/* LID_BTN */
				MX6QDL_PAD_GPIO_4__GPIO1_IO04		0x030b0
				/* SLP_BTN */
				MX6QDL_PAD_GPIO_5__GPIO1_IO05		0x030b0
				/* BATTERY LOW */
				MX6QDL_PAD_GPIO_6__GPIO1_IO06		0x030b0
				/* THRM */
				MX6QDL_PAD_GPIO_7__GPIO1_IO07		0x0b0b0
				/* WAKE */
				MX6QDL_PAD_GPIO_8__GPIO1_IO08		0x030b0
				/* WDOUT_ENn */
				MX6QDL_PAD_GPIO_9__GPIO1_IO09		0x0b0b0
				/* WATCHDOG TRIGGER */
				MX6QDL_PAD_DISP0_DAT7__GPIO4_IO28	0x0b0b0
				/* SATA_ACT */
				MX6QDL_PAD_GPIO_18__GPIO7_IO13		0x0b0b0

				/* PCIe-RST, also used as touch reset */
				MX6QDL_PAD_DISP0_DAT10__GPIO4_IO31	0x030b0
			>;
		};

		/* Pins already set in bootloader */
#if 0
		pinctrl_gpmi_nand_1: gpmi-nand-1 {
			fsl,pins = <
				MX6QDL_PAD_NANDF_CLE__NAND_CLE		0x0b0b1
				MX6QDL_PAD_NANDF_ALE__NAND_ALE		0x0b0b1
				MX6QDL_PAD_NANDF_WP_B__NAND_WP_B	0x0b0b1
				MX6QDL_PAD_NANDF_RB0__NAND_READY_B	0x0b000
				MX6QDL_PAD_NANDF_CS0__NAND_CE0_B	0x0b0b1
				MX6QDL_PAD_SD4_CMD__NAND_RE_B		0x0b0b1
				MX6QDL_PAD_SD4_CLK__NAND_WE_B		0x0b0b1
				MX6QDL_PAD_NANDF_D0__NAND_DATA00	0x0b0b1
				MX6QDL_PAD_NANDF_D1__NAND_DATA01	0x0b0b1
				MX6QDL_PAD_NANDF_D2__NAND_DATA02	0x0b0b1
				MX6QDL_PAD_NANDF_D3__NAND_DATA03	0x0b0b1
				MX6QDL_PAD_NANDF_D4__NAND_DATA04	0x0b0b1
				MX6QDL_PAD_NANDF_D5__NAND_DATA05	0x0b0b1
				MX6QDL_PAD_NANDF_D6__NAND_DATA06	0x0b0b1
				MX6QDL_PAD_NANDF_D7__NAND_DATA07	0x0b0b1
			>;
		};
#endif

#ifdef CONFIG_QBLISSA9_SPI_FLASH
		/* ECSPI1 - SPI flash */
		pinctrl_ecspi1_1: ecspi1grp {
			fsl,pins = <
				MX6QDL_PAD_EIM_D17__ECSPI1_MISO		0x100b1
				MX6QDL_PAD_EIM_D18__ECSPI1_MOSI		0x100b1
				MX6QDL_PAD_EIM_D16__ECSPI1_SCLK		0x100b1
			>;
		};

		pinctrl_ecspi1_cs: ecspi1cs {
			fsl,pins = <
				/* ECSPI1_SS0 - slave (chip) select 0 */
				MX6QDL_PAD_EIM_EB2__GPIO2_IO30		0x1b0b0
			>;
		};
#endif /* CONFIG_QBLISSA9_SPI_FLASH */

#ifdef CONFIG_QBLISSA9_SPI_A
		/* ECSPI2 - SPI_A */
		pinctrl_ecspi2_1: ecspi2grp {
			fsl,pins = <
				MX6QDL_PAD_EIM_OE__ECSPI2_MISO 		0x100b1
				MX6QDL_PAD_EIM_CS1__ECSPI2_MOSI		0x100b1
				MX6QDL_PAD_EIM_CS0__ECSPI2_SCLK		0x100b1
			>;
		};

		pinctrl_ecspi2_cs: ecspi2cs {
			fsl,pins = <
				/* ECSPI2_SS0 - slave (chip) select 0 */
				MX6QDL_PAD_EIM_RW__GPIO2_IO26		0x1b0b0
				/* ECSPI2_SS1  - slave (chip) select 1 */
				MX6QDL_PAD_EIM_LBA__GPIO2_IO27		0x1b0b0
			>;
		};
#endif

#ifdef CONFIG_QBLISSA9_UART_A
		pinctrl_uart3_1: uart3grp-1{
			fsl,pins = <
				MX6QDL_PAD_EIM_D24__UART3_TX_DATA	0x1b0b1
				MX6QDL_PAD_EIM_D25__UART3_RX_DATA	0x1b0b1
				MX6QDL_PAD_EIM_D23__UART3_CTS_B		0x1b0b1
				MX6QDL_PAD_EIM_EB3__UART3_RTS_B		0x1b0b1
			>;
		};
#endif

#ifdef CONFIG_QBLISSA9_UART_B
		pinctrl_uart5_1: uart5grp-1{
			fsl,pins = <
				MX6QDL_PAD_KEY_COL1__UART5_TX_DATA	0x1b0b1
				MX6QDL_PAD_KEY_ROW1__UART5_RX_DATA	0x1b0b1
			>;
		};
#endif

#ifdef CONFIG_QBLISSA9_UART_C
		pinctrl_uart2_1: uart2grp-1{
			fsl,pins = <
				MX6QDL_PAD_EIM_D26__UART2_TX_DATA	0x1b0b1
				MX6QDL_PAD_EIM_D27__UART2_RX_DATA	0x1b0b1
				MX6QDL_PAD_EIM_D28__UART2_CTS_B		0x1b0b1
				MX6QDL_PAD_EIM_D29__UART2_RTS_B		0x1b0b1
			>;
		};
#endif

#ifdef CONFIG_QBLISSA9_BLUETOOTH
		pinctrl_uart1_1: uart1grp-1{
			fsl,pins = <
				MX6QDL_PAD_CSI0_DAT10__UART1_TX_DATA	0x1b0b1
				MX6QDL_PAD_CSI0_DAT11__UART1_RX_DATA	0x1b0b1
				MX6QDL_PAD_EIM_D19__UART1_CTS_B		0x1b0b1
				MX6QDL_PAD_EIM_D20__UART1_RTS_B		0x1b0b1
			>;
		};
#endif

		pinctrl_flexcan2: flexcan2grp {
			fsl,pins = <
				MX6QDL_PAD_KEY_COL4__FLEXCAN2_TX	0x1b020
				MX6QDL_PAD_KEY_ROW4__FLEXCAN2_RX	0x1b020
			>;
		};

		pinctrl_usbotg: usbotggrp {
			fsl,pins = <
				/* USB OTG PWR, active low */
//###				MX6QDL_PAD_EIM_D22__GPIO3_IO22		0x0b030
				MX6QDL_PAD_EIM_D22__USB_OTG_PWR		0x0b030
#ifdef CONFIG_QBLISSA9_HAVE_USB_OTG_OC
				/* USB_OTG_OC (part of USB_OC01), active low */
				MX6QDL_PAD_EIM_D21__USB_OTG_OC		0x1b000
#endif
				/* USB_OTG_ID: low: host, open: device */
				MX6QDL_PAD_ENET_RX_ER__USB_OTG_ID	0x1b000
			>;
		};

		pinctrl_usbh1: usbh1grp {
			fsl,pins = <
				/* USB hub reset line, active low */
				MX6QDL_PAD_GPIO_17__GPIO7_IO12		0x0b0b0
				/* USB H1 host power is always on */
			>;
		};

#ifdef CONFIG_QBLISSA9_WM9715_AUDIO
		pinctrl_ac97_running: ac97_running {
			fsl,pins = <
				MX6QDL_PAD_DI0_PIN2__AUD6_TXD		0x170b9
				MX6QDL_PAD_DI0_PIN3__AUD6_TXFS		0x170b9
				MX6QDL_PAD_DI0_PIN4__AUD6_RXD		0x120f9
				MX6QDL_PAD_DI0_PIN15__AUD6_TXC		0x120f9
				MX6QDL_PAD_DI0_DISP_CLK__GPIO4_IO16	0x1b0b0
			>;
		};

		pinctrl_ac97_warm_reset: ac97_warm_reset {
			fsl,pins = <
				MX6QDL_PAD_DI0_PIN2__AUD6_TXD		0x170b9
				MX6QDL_PAD_DI0_PIN3__GPIO4_IO19		0x170b9
				MX6QDL_PAD_DI0_PIN4__AUD6_RXD		0x120f9
				MX6QDL_PAD_DI0_PIN15__AUD6_TXC		0x120f9
				MX6QDL_PAD_DI0_DISP_CLK__GPIO4_IO16	0x1b0b0
			>;
		};

		pinctrl_ac97_reset: ac97_reset {
			fsl,pins = <
				MX6QDL_PAD_DI0_PIN2__GPIO4_IO18		0x170b9
				MX6QDL_PAD_DI0_PIN3__GPIO4_IO19		0x170b9
				MX6QDL_PAD_DI0_PIN4__AUD6_RXD		0x120f9
				MX6QDL_PAD_DI0_PIN15__AUD6_TXC		0x120f9
				MX6QDL_PAD_DI0_DISP_CLK__GPIO4_IO16	0x1b0b0
			>;
		};
#endif

		pinctrl_enet: enetgrp {
			fsl,pins = <
				MX6QDL_PAD_ENET_MDIO__ENET_MDIO		0x1b0b0
				MX6QDL_PAD_ENET_MDC__ENET_MDC		0x1b0b0
				MX6QDL_PAD_RGMII_TXC__RGMII_TXC		0x1b0b0
				MX6QDL_PAD_RGMII_TD0__RGMII_TD0		0x1b0b0
				MX6QDL_PAD_RGMII_TD1__RGMII_TD1		0x1b0b0
				MX6QDL_PAD_RGMII_TD2__RGMII_TD2		0x1b0b0
				MX6QDL_PAD_RGMII_TD3__RGMII_TD3		0x1b0b0
				MX6QDL_PAD_RGMII_TX_CTL__RGMII_TX_CTL	0x1b0b0
				MX6QDL_PAD_ENET_REF_CLK__ENET_TX_CLK	0x1b0b0
				MX6QDL_PAD_RGMII_RXC__RGMII_RXC		0x1b0b0
				MX6QDL_PAD_RGMII_RD0__RGMII_RD0		0x1b0b0
				MX6QDL_PAD_RGMII_RD1__RGMII_RD1		0x1b0b0
				MX6QDL_PAD_RGMII_RD2__RGMII_RD2		0x1b0b0
				MX6QDL_PAD_RGMII_RD3__RGMII_RD3		0x1b0b0
				MX6QDL_PAD_RGMII_RX_CTL__RGMII_RX_CTL	0x1b0b0
				/* Phy interrupt IO pin*/
				MX6QDL_PAD_GPIO_19__GPIO4_IO05		0x4001b0a8
				/* Phy reset IO pin*/
				MX6QDL_PAD_ENET_CRS_DV__GPIO1_IO25	0x4001b0a8
			>;
		};

#if 0 /* NOT TESTED */
#ifdef CONFIG_QBLISSA9_WLAN
		pinctrl_usdhc1:usdhc1grp {
			fsl,pins = <
				MX6QDL_PAD_SD1_CMD__SD1_CMD		0x17091
				MX6QDL_PAD_SD1_CLK__SD1_CLK		0x10091
				MX6QDL_PAD_SD1_DAT0__SD1_DATA0		0x17091
				MX6QDL_PAD_SD1_DAT1__SD1_DATA1		0x17091
				MX6QDL_PAD_SD1_DAT2__SD1_DATA2		0x17091
				MX6QDL_PAD_SD1_DAT3__SD1_DATA3		0x17091
				MX6QDL_PAD_ENET_RXD0__ESAI_TX_HF_CLK	0x10091
				MX6QDL_PAD_SD2_CMD__GPIO1_IO11		0x030b0
				MX6QDL_PAD_SD2_CLK__GPIO1_IO10		0x030b0
				MX6QDL_PAD_SD2_DAT0__GPIO1_IO15		0x030b0
			>;
		};
#endif
#endif

#ifdef CONFIG_QBLISSA9_SD_A
		pinctrl_usdhc3: usdhc3grp {
			fsl,pins = <
				MX6QDL_PAD_SD3_CMD__SD3_CMD		0x170b1
				MX6QDL_PAD_SD3_CLK__SD3_CLK		0x100b1
				MX6QDL_PAD_SD3_DAT0__SD3_DATA0		0x170b1
				MX6QDL_PAD_SD3_DAT1__SD3_DATA1		0x170b1
				MX6QDL_PAD_SD3_DAT2__SD3_DATA2		0x170b1
				MX6QDL_PAD_SD3_DAT3__SD3_DATA3		0x170b1
#ifdef CONFIG_QBLISSA9_SD_A_8BIT
				MX6QDL_PAD_SD3_DAT4__SD3_DATA4		0x170b1
				MX6QDL_PAD_SD3_DAT5__SD3_DATA5		0x170b1
				MX6QDL_PAD_SD3_DAT6__SD3_DATA6		0x170b1
				MX6QDL_PAD_SD3_DAT7__SD3_DATA7		0x170b1
#endif
				/* Reset eMMC, active low */
				MX6QDL_PAD_SD3_RST__GPIO7_IO08		0x170b1
#ifdef CONFIG_QBLISSA9_SD_A_CD
				/* Card Detect (CD), active low (pull-up) */
				MX6QDL_PAD_NANDF_CS2__GPIO6_IO15	0x17000
#endif
#ifdef CONFIG_QBLISSA9_SD_A_WP
				/*
				 * Write Protect (WP), active high (pull-up)
				 * lock:   WP switch open, pulled high
				 * unlock: WP switch closed, connects to GND
				 */
				MX6QDL_PAD_SD2_DAT2__GPIO1_IO13		0x17000
#endif
			>;
		};
#endif

#ifdef CONFIG_QBLISSA9_I2C_A
		pinctrl_i2c3: i2c3grp-1 {
			fsl,pins = <
				MX6QDL_PAD_GPIO_3__I2C3_SCL		0x4001b8b1
				MX6QDL_PAD_GPIO_16__I2C3_SDA		0x4001b8b1
				/* if AD Converter */
				//MX6QDL_PAD_SD4_DAT4__GPIO2_IO12	0x80000000
			>;
		};
#endif

#ifdef CONFIG_QBLISSA9_I2C_B
		pinctrl_i2c_gpio_b: i2c_gpio_grp_b {
			fsl,pins = <
				MX6QDL_PAD_DISP0_DAT0__GPIO4_IO21	0x17030
				MX6QDL_PAD_DISP0_DAT1__GPIO4_IO22	0x17030
				/* IRQ */
				MX6QDL_PAD_DISP0_DAT2__GPIO4_IO23	0x17000
			>;
		};
#endif

#ifdef CONFIG_QBLISSA9_I2C_C
		pinctrl_i2c_gpio_c: i2c_gpio_c_grp {
			fsl,pins = <
				/* LDDC_DATA */
				MX6QDL_PAD_SD4_DAT4__GPIO2_IO12		0x17030
				/* LDDC_CLK */
				MX6QDL_PAD_SD4_DAT5__GPIO2_IO13		0x17030
			>;
		};
#endif

#ifdef CONFIG_QBLISSA9_I2C_D
		pinctrl_i2c2: i2c2grp {
			fsl,pins = <
				MX6QDL_PAD_KEY_COL3__I2C2_SCL		0x4001b8b1
				MX6QDL_PAD_KEY_ROW3__I2C2_SDA		0x4001b8b1
			>;
		};
#endif

#ifdef CONFIG_QBLISSA9_HDMI
		pinctrl_i2c_gpio_hdmi: i2c6_gpio_hdmi_grp {
			fsl,pins = <
				MX6QDL_PAD_SD4_DAT6__GPIO2_IO14		0x03039
				MX6QDL_PAD_SD4_DAT7__GPIO2_IO15		0x03039
			>;
		};
#endif

#ifdef CONFIG_QBLISSA9_PARALLEL_CAMERA
		pinctrl_i2c1: i2c1grp {
			fsl,pins = <
				MX6QDL_PAD_CSI0_DAT8__I2C1_SDA		0x4001b8b1
				MX6QDL_PAD_CSI0_DAT9__I2C1_SCL		0x4001b8b1
			>;
		};

		pinctrl_ipu1_2: ipu1grp-cam {
			fsl,pins = <
				MX6QDL_PAD_CSI0_DAT12__IPU1_CSI0_DATA12	0x80000000
				MX6QDL_PAD_CSI0_DAT13__IPU1_CSI0_DATA13	0x80000000
				MX6QDL_PAD_CSI0_DAT14__IPU1_CSI0_DATA14	0x80000000
				MX6QDL_PAD_CSI0_DAT15__IPU1_CSI0_DATA15	0x80000000
				MX6QDL_PAD_CSI0_DAT16__IPU1_CSI0_DATA16	0x80000000
				MX6QDL_PAD_CSI0_DAT17__IPU1_CSI0_DATA17	0x80000000
				MX6QDL_PAD_CSI0_DAT18__IPU1_CSI0_DATA18	0x80000000
				MX6QDL_PAD_CSI0_DAT19__IPU1_CSI0_DATA19	0x80000000
				/*reset */
				MX6QDL_PAD_CSI0_PIXCLK__IPU1_CSI0_PIXCLK 0x80000000
				MX6QDL_PAD_CSI0_DATA_EN__IPU1_CSI0_DATA_EN 0x80000000
				MX6QDL_PAD_CSI0_MCLK__IPU1_CSI0_HSYNC	0x80000000
				MX6QDL_PAD_CSI0_VSYNC__IPU1_CSI0_VSYNC	0x80000000
				MX6QDL_PAD_GPIO_0__CCM_CLKO1		0x170f9
				MX6QDL_PAD_CSI0_DAT6__IPU1_CSI0_DATA06	0x80000000
				MX6QDL_PAD_CSI0_DAT5__IPU1_CSI0_DATA05	0x80000000
			>;
		};
#endif /* CONFIG_QBLISSA9_PARALLEL_CAMERA */

#ifdef CONFIG_QBLISSA9_PWM_A
		pinctrl_pwm3: pwm3grp {
			fsl,pins = <
				MX6QDL_PAD_SD4_DAT1__PWM3_OUT		0x110b0
			>;
		};
#endif

#ifdef CONFIG_QBLISSA9_PWM_B
		pinctrl_pwm1: pwm1grp {
			fsl,pins = <
				MX6QDL_PAD_DISP0_DAT8__PWM1_OUT		0x110b0
			>;
		};
#endif

#ifdef CONFIG_QBLISSA9_PWM_C
		pinctrl_pwm4: pwm4grp {
			fsl,pins = <
				MX6QDL_PAD_SD4_DAT2__PWM4_OUT		0x110b0
			>;
		};
#endif

#ifdef CONFIG_QBLISSA9_PCIE
		pinctrl_pcie: pciegrp {
			fsl,pins = <
#if (CONFIG_QBLISSA9_BOARD_REVISION >= 120)
				/* PCIE_WAKE */
				MX6QDL_PAD_GPIO_8__GPIO1_IO08		0x1b0b0
#endif
				/* PCIE_RST: see above in Hog */
			>;
		};
#endif

		pinctrl_status_leds: ledgrp {
			fsl,pins = <
				MX6QDL_PAD_KEY_COL0__GPIO4_IO06		0x030b0
				MX6QDL_PAD_KEY_ROW0__GPIO4_IO07		0x030b0
			>;
		};
	};
};
